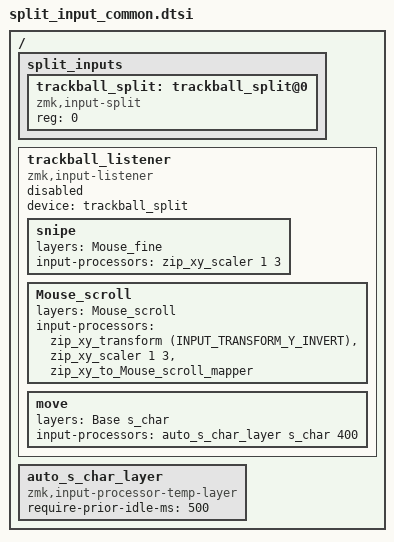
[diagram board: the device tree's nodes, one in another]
#include <dt-bindings/zmk/input_transform.h>
#include <input/processors.dtsi>

#define Base 0
#define s_char 1
#define szch 2
#define brackets 3
#define num 4
#define fn 5
#define Mouse 6
#define Mouse_scroll 7
#define Mouse_fine 8

/ {
  split_inputs {
    #address-cells = <1>;
    #size-cells = <0>;

    trackball_split: trackball_split@0 {
      compatible = "zmk,input-split";
      reg = <0>;
    };
  };

  trackball_listener: trackball_listener {
    compatible = "zmk,input-listener";
    status = "disabled";
    device = <&trackball_split>;

    snipe {
      layers = <Mouse_fine>;
      input-processors = <&zip_xy_scaler 1 3>;
    };

    Mouse_scroll {
      layers = <Mouse_scroll>;
      input-processors = <&zip_xy_transform (INPUT_TRANSFORM_Y_INVERT)>, <&zip_xy_scaler 1 3>, <&zip_xy_to_Mouse_scroll_mapper>;
    };

    move {
      layers = <Base s_char>;
      input-processors = <&auto_s_char_layer s_char 400>;
    };
  };

  auto_s_char_layer: auto_s_char_layer {
    compatible = "zmk,input-processor-temp-layer";
    #input-processor-cells = <2>;
    require-prior-idle-ms = <500>;  // was 500 -fjw-   
  };
};
